# S32K142W_M4 register map
Vendor: NXP Semiconductors; File version: 1.0
CPU: CM4 r0p1, little endian, MPU, FPU, VTOR, 4 interrupt priority bits
Registers are 32-bit, read-write, reset 0x0 unless marked. A register's access mark holds for its fields unless they carry their own. Offsets are from the block's base; [hi:lo] are bit positions; lines under a group give offsets from that group; {n}, {i} and the like mark numbered series; 'fields as' and 'values as' point back to an identical list.

## FLEXCAN0 — CAN
Base 0x40024000
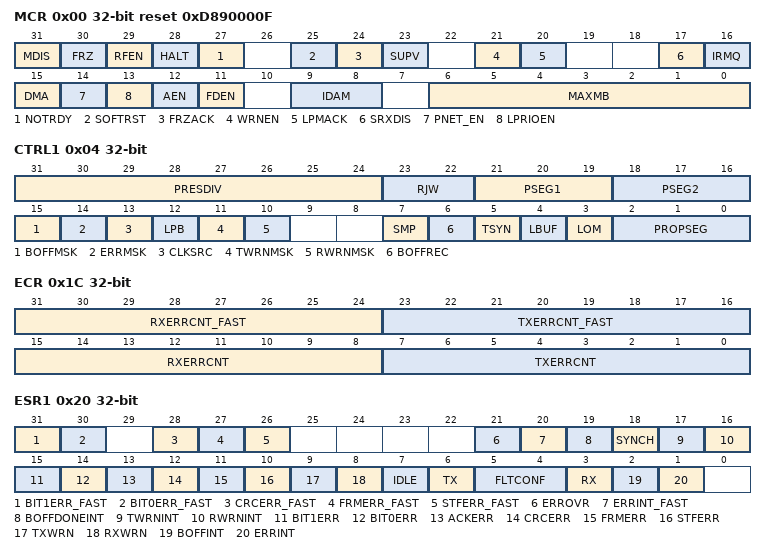
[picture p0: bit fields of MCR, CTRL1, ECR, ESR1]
0x00 MCR reset 0xD890000F — Module Configuration register
  [31] MDIS — Module Disable
    0=flexcan_enabled (Enable the FlexCAN module.); 1=flexcan_disabled (Disable the FlexCAN module.)
  [30] FRZ — Freeze Enable
    0=freeze_mode_disabled (Not enabled to enter Freeze mode.); 1=freeze_mode_enabled (Enabled to enter Freeze mode.)
  [29] RFEN — Rx FIFO Enable
    0=id2 (Rx FIFO not enabled.); 1=id4 (Rx FIFO enabled.)
  [28] HALT — Halt FlexCAN
    0=HALT_disable (No Freeze mode request.); 1=HALT_enable (Enters Freeze mode if the FRZ bit is asserted.)
  [27] NOTRDY ro — FlexCAN Not Ready
    0=id1 (FlexCAN module is either in Normal mode, Listen-Only mode, or Loop-Back mode.); 1=id4 (FlexCAN module is either in Disable mode, Stop mode, or Freeze mode.)
  [25] SOFTRST — Soft Reset
    0=SOFTRST_no_reset_request (No reset request.); 1=SOFTRST_reset_registers (Resets the registers affected by soft reset.)
  [24] FRZACK ro — Freeze Mode Acknowledge
    0=freeze_mode_no (FlexCAN not in Freeze mode, prescaler running.); 1=freeze_mode_yes (FlexCAN in Freeze mode, prescaler stopped.)
  [23] SUPV — Supervisor Mode
    0=id2 (FlexCAN is in User mode. Affected registers allow both Supervisor and Unrestricted accesses.); 1=id4 (FlexCAN is in Supervisor mode. Affected registers allow only Supervisor access. Unrestricted access behaves as though the access was done to an unimplemented register location.)
  [21] WRNEN — Warning Interrupt Enable
    0=TWRNINT_RWRNINT_inactive (TWRNINT and RWRNINT bits are zero, independent of the values in the error counters.); 1=TWRNINT_RWRNINT_active (TWRNINT and RWRNINT bits are set when the respective error counter transitions from less than 96 to greater than or equal to 96.)
  [20] LPMACK ro — Low-Power Mode Acknowledge
    0=low_power_no (FlexCAN is not in a low-power mode.); 1=low_power_yes (FlexCAN is in a low-power mode.)
  [17] SRXDIS — Self Reception Disable
    0=self_reception_enabled; 1=self_reception_disabled
  [16] IRMQ — Individual Rx Masking And Queue Enable
    0=individual_rx_masking_disabled (Individual Rx masking and queue feature are disabled. For backward compatibility with legacy applications, the reading of C/S word locks the MB even if it is EMPTY.); 1=individual_rx_masking_enabled (Individual Rx masking and queue feature are enabled.)
  [15] DMA — DMA Enable
    0=id2 (DMA feature for RX FIFO disabled.); 1=id4 (DMA feature for RX FIFO enabled.)
  [14] PNET_EN — Pretended Networking Enable
    0=PN_disabled (Pretended Networking mode is disabled.); 1=PN_enabled (Pretended Networking mode is enabled.)
  [13] LPRIOEN — Local Priority Enable
    0=local_priority_disabled; 1=local_priority_enabled
  [12] AEN — Abort Enable
    0=abort_disabled; 1=abort_enabled
  [11] FDEN — CAN FD operation enable
    0=CAN_FD_disabled (CAN FD is disabled. FlexCAN is able to receive and transmit messages in CAN 2.0 format.); 1=CAN_FD_enabled (CAN FD is enabled. FlexCAN is able to receive and transmit messages in both CAN FD and CAN 2.0 formats.)
  [9:8] IDAM — ID Acceptance Mode
    0=one_full_ID (Format A: One full ID (standard and extended) per ID filter table element.); 1=two_full_ID (Format B: Two full standard IDs or two partial 14-bit (standard and extended) IDs per ID filter table element.); 2=four_partial_ID (Format C: Four partial 8-bit standard IDs per ID filter table element.); 3=all_frames_rejected (Format D: All frames rejected.)
  [6:0] MAXMB — Number Of The Last Message Buffer
0x04 CTRL1 — Control 1 register
  [31:24] PRESDIV — Prescaler Division Factor
  [23:22] RJW — Resync Jump Width
  [21:19] PSEG1 — Phase Segment 1
  [18:16] PSEG2 — Phase Segment 2
  [15] BOFFMSK — Bus Off Interrupt Mask
    0=bus_off_int_disabled (Bus Off interrupt disabled.); 1=bus_off_int_enabled (Bus Off interrupt enabled.)
  [14] ERRMSK — Error Interrupt Mask
    0=error_int_disabled (Error interrupt disabled.); 1=error_int_enabled (Error interrupt enabled.)
  [13] CLKSRC — CAN Engine Clock Source
    0=oscillator_clock (The CAN engine clock source is the oscillator clock. Under this condition, the oscillator clock frequency must be lower than the bus clock.); 1=peripheral_clock (The CAN engine clock source is the peripheral clock.)
  [12] LPB — Loop Back Mode
    0=loopback_disabled; 1=loopback_enabled
  [11] TWRNMSK — Tx Warning Interrupt Mask
    0=tx_warning_int_disabled (Tx Warning interrupt disabled.); 1=tx_warning_int_enabled (Tx Warning interrupt enabled.)
  [10] RWRNMSK — Rx Warning Interrupt Mask
    0=rx_warning_int_disabled (Rx Warning interrupt disabled.); 1=rx_warning_int_enabled (Rx Warning interrupt enabled.)
  [7] SMP — CAN Bit Sampling
    0=one_sample (Just one sample is used to determine the bit value.); 1=Three samples are used to determine the value of the received bit: the regular one (sample point) and two preceding samples; a majority rule is used
  [6] BOFFREC — Bus Off Recovery
    0=auto_recover_enabled (Automatic recovering from Bus Off state enabled.); 1=auto_recover_disabled (Automatic recovering from Bus Off state disabled.)
  [5] TSYN — Timer Sync
    0=timer_sync_disabled (Timer sync feature disabled); 1=timer_sync_enabled (Timer sync feature enabled)
  [4] LBUF — Lowest Buffer Transmitted First
    0=highest_buffer_first (Buffer with highest priority is transmitted first.); 1=lowest_buffer_first (Lowest number buffer is transmitted first.)
  [3] LOM — Listen-Only Mode
    0=listen_only_mode_disabled (Listen-Only mode is deactivated.); 1=listen_only_mode_enabled (FlexCAN module operates in Listen-Only mode.)
  [2:0] PROPSEG — Propagation Segment
0x08 TIMER — Free Running Timer
  [15:0] TIMER — Timer Value
0x10 RXMGMASK reset not defined — Rx Mailboxes Global Mask register
  [31:0] MG — Rx Mailboxes Global Mask Bits
0x14 RX14MASK reset not defined
  [31:0] RX14M — Rx Buffer 14 Mask Bits
0x18 RX15MASK reset not defined
  [31:0] RX15M — Rx Buffer 15 Mask Bits
0x1C ECR — Error Counter
  [31:24] RXERRCNT_FAST — Receive Error Counter for fast bits
  [23:16] TXERRCNT_FAST — Transmit Error Counter for fast bits
  [15:8] RXERRCNT — Receive Error Counter
  [7:0] TXERRCNT — Transmit Error Counter
0x20 ESR1 — Error and Status 1 register
  [31] BIT1ERR_FAST ro — Bit1 Error in the Data Phase of CAN FD frames with the BRS bit set
    0=bit1_error_no (No such occurrence.); 1=bit1_error_yes (At least one bit sent as recessive is received as dominant.)
  [30] BIT0ERR_FAST ro — Bit0 Error in the Data Phase of CAN FD frames with the BRS bit set
    0=bit0_error_no (No such occurrence.); 1=bit0_error_yes (At least one bit sent as dominant is received as recessive.)
  [28] CRCERR_FAST ro — Cyclic Redundancy Check Error in the CRC field of CAN FD frames with the BRS bit set
    0=CRC_error_no (No such occurrence.); 1=CRC_error_yes (A CRC error occurred since last read of this register.)
  [27] FRMERR_FAST ro — Form Error in the Data Phase of CAN FD frames with the BRS bit set
    0=form_error_no (No such occurrence.); 1=form_error_yes (A form error occurred since last read of this register.)
  [26] STFERR_FAST ro — Stuffing Error in the Data Phase of CAN FD frames with the BRS bit set
    0=stuffing_error_no (No such occurrence.); 1=stuffing_error_yes (A stuffing error occurred since last read of this register.)
  [21] ERROVR write-1-clears — Error Overrun
    0=overrun_not_occurred (Overrun has not occurred.); 1=overrun_occurred (Overrun has occurred.)
  [20] ERRINT_FAST write-1-clears — Error interrupt for errors detected in Data Phase of CAN FD frames with BRS bit set
    0=errors_data_phase_no (No such occurrence.); 1=errors_data_phase_yes (Indicates setting of any error bit detected in the data phase of CAN FD frames with the BRS bit set.)
  [19] BOFFDONEINT write-1-clears — Bus Off Done Interrupt
    0=bus_off_not_done (No such occurrence.); 1=bus_off_done (FlexCAN module has completed Bus Off process.)
  [18] SYNCH ro — CAN Synchronization Status
    0=CAN_bus_sync_no (FlexCAN is not synchronized to the CAN bus.); 1=CAN_bus_sync_yes (FlexCAN is synchronized to the CAN bus.)
  [17] TWRNINT write-1-clears — Tx Warning Interrupt Flag
    0=Tx_warning_int_no (No such occurrence.); 1=Tx_warning_int_yes (The Tx error counter transitioned from less than 96 to greater than or equal to 96.)
  [16] RWRNINT write-1-clears — Rx Warning Interrupt Flag
    0=Rx_warning_int_no (No such occurrence.); 1=Rx_warning_int_yes (The Rx error counter transitioned from less than 96 to greater than or equal to 96.)
  [15] BIT1ERR ro — Bit1 Error
    values as BIT1ERR_FAST
  [14] BIT0ERR ro — Bit0 Error
    values as BIT0ERR_FAST
  [13] ACKERR ro — Acknowledge Error
    0=ACK_error_no (No such occurrence.); 1=ACK_error_yes (An ACK error occurred since last read of this register.)
  [12] CRCERR ro — Cyclic Redundancy Check Error
    values as CRCERR_FAST
  [11] FRMERR ro — Form Error
    0=form_error_no (No such occurrence.); 1=form_error_yes (A Form Error occurred since last read of this register.)
  [10] STFERR ro — Stuffing Error
    values as STFERR_FAST
  [9] TXWRN ro — TX Error Warning
    0=TXERRCNT_LT_96 (No such occurrence.); 1=TXERRCNT_GTE_96 (TXERRCNT is greater than or equal to 96.)
  [8] RXWRN ro — Rx Error Warning
    0=RXERRCNT_LT_96 (No such occurrence.); 1=RXERRCNT_GTE_96 (RXERRCNT is greater than or equal to 96.)
  [7] IDLE ro
    0=can_bus_not_idle (No such occurrence.); 1=can_bus_idle (CAN bus is now IDLE.)
  [6] TX ro — FlexCAN In Transmission
    0=transmit_message_no (FlexCAN is not transmitting a message.); 1=transmit_message_yes (FlexCAN is transmitting a message.)
  [5:4] FLTCONF ro — Fault Confinement State
    0=error_active; 1=error_passive; 0b1x=bus_off
  [3] RX ro — FlexCAN In Reception
    0=DISABLE (FlexCAN is not receiving a message.); 1=ENABLE (FlexCAN is receiving a message.)
  [2] BOFFINT write-1-clears — Bus Off Interrupt
    0=DISABLE (No such occurrence.); 1=ENABLE (FlexCAN module entered Bus Off state.)
  [1] ERRINT write-1-clears — Error Interrupt
    0=DISABLE (No such occurrence.); 1=ENABLE (Indicates setting of any error bit in the Error and Status register.)
0x24 IMASK2 — Interrupt Masks 2 register
  [31:0] BUF63TO32M — Buffer MB i Mask
0x28 IMASK1 — Interrupt Masks 1 register
  [31:0] BUF31TO0M — Buffer MB i Mask
0x2C IFLAG2 — Interrupt Flags 2 register
  [31:0] BUF63TO32I write-1-clears — Buffer MB i Interrupt
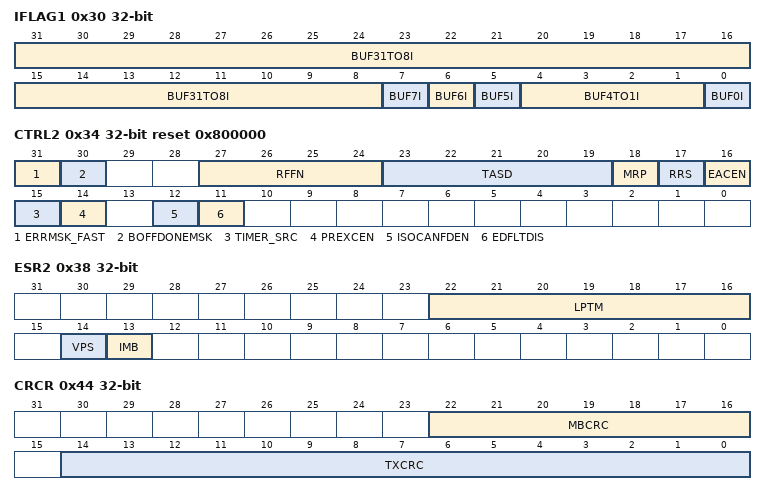
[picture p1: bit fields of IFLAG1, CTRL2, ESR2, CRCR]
0x30 IFLAG1 — Interrupt Flags 1 register
  [31:8] BUF31TO8I write-1-clears — Buffer MBi Interrupt
  [7] BUF7I write-1-clears — Buffer MB7 Interrupt Or Rx FIFO Overflow
    0=id2 (No occurrence of MB7 completing transmission/reception when MCR[RFEN]=0, or of Rx FIFO overflow when MCR[RFEN]=1); 1=id4 (MB7 completed transmission/reception when MCR[RFEN]=0, or Rx FIFO overflow when MCR[RFEN]=1)
  [6] BUF6I write-1-clears — Buffer MB6 Interrupt Or Rx FIFO Warning
    0=id2 (No occurrence of MB6 completing transmission/reception when MCR[RFEN]=0, or of Rx FIFO almost full when MCR[RFEN]=1); 1=id4 (MB6 completed transmission/reception when MCR[RFEN]=0, or Rx FIFO almost full when MCR[RFEN]=1)
  [5] BUF5I write-1-clears — Buffer MB5 Interrupt Or Frames available in Rx FIFO
    0=id2 (No occurrence of MB5 completing transmission/reception when MCR[RFEN]=0, or of frame(s) available in the FIFO, when MCR[RFEN]=1); 1=id4 (MB5 completed transmission/reception when MCR[RFEN]=0, or frame(s) available in the Rx FIFO when MCR[RFEN]=1. It generates a DMA request in case of MCR[RFEN] and MCR[DMA] are enabled.)
  [4:1] BUF4TO1I write-1-clears — Buffer MB i Interrupt Or Reserved
  [0] BUF0I write-1-clears — Buffer MB0 Interrupt Or Clear FIFO bit
    0=buffer_Tx_Rx_not_complete (The corresponding buffer has no occurrence of successfully completed transmission or reception when MCR[RFEN]=0.); 1=buffer_Tx_Rx_complete (The corresponding buffer has successfully completed transmission or reception when MCR[RFEN]=0.)
0x34 CTRL2 reset 0x800000 — Control 2 register
  [31] ERRMSK_FAST — Error Interrupt Mask for errors detected in the data phase of fast CAN FD frames
    0=DISABLE (ERRINT_FAST error interrupt disabled.); 1=ENABLE (ERRINT_FAST error interrupt enabled.)
  [30] BOFFDONEMSK — Bus Off Done Interrupt Mask
    0=DISABLE (Bus off done interrupt disabled.); 1=ENABLE (Bus off done interrupt enabled.)
  [27:24] RFFN — Number Of Rx FIFO Filters
  [23:19] TASD — Tx Arbitration Start Delay
  [18] MRP — Mailboxes Reception Priority
    0=id2 (Matching starts from Rx FIFO or Enhanced Rx FIFO and continues on mailboxes.); 1=id4 (Matching starts from mailboxes and continues on Rx FIFO.)
  [17] RRS — Remote Request Storing
    0=remote_response_frame_not_generated (Remote response frame is generated.); 1=remote_response_frame_generated (Remote request frame is stored.)
  [16] EACEN — Entire Frame Arbitration Field Comparison Enable For Rx Mailboxes
    0=RTR_compare_no (Rx mailbox filter's IDE bit is always compared and RTR is never compared despite mask bits.); 1=RTR_compare_yes (Enables the comparison of both Rx mailbox filter's IDE and RTR bit with their corresponding bits within the incoming frame. Mask bits do apply.)
  [15] TIMER_SRC — Timer Source
    0=CAN_bit_clock (The free running timer is clocked by the CAN bit clock, which defines the baud rate on the CAN bus.); 1=external_clock (The free running timer is clocked by an external time tick. The period can be either adjusted to be equal to the baud rate on the CAN bus, or a different value as required. See the device-specific section for details about the external time tick.)
  [14] PREXCEN — Protocol Exception Enable
    0=DISABLE (Protocol exception is disabled.); 1=ENABLE (Protocol exception is enabled.)
  [12] ISOCANFDEN — ISO CAN FD Enable
    0=non_ISO (FlexCAN operates using the non-ISO CAN FD protocol.); 1=ISO (FlexCAN operates using the ISO CAN FD protocol (ISO 11898-1).)
  [11] EDFLTDIS — Edge Filter Disable
    0=ENABLE (Edge filter is enabled); 1=DISABLE (Edge filter is disabled)
0x38 ESR2 ro — Error and Status 2 register
  [22:16] LPTM — Lowest Priority Tx Mailbox
  [14] VPS — Valid Priority Status
    0=invalid (Contents of IMB and LPTM are invalid.); 1=valid (Contents of IMB and LPTM are valid.)
  [13] IMB — Inactive Mailbox
    0=inactive_mailbox_no (If ESR2[VPS] is asserted, the ESR2[LPTM] is not an inactive mailbox.); 1=inactive_mailbox_yes (If ESR2[VPS] is asserted, there is at least one inactive mailbox. LPTM content is the number of the first one.)
0x44 CRCR ro — CRC register
  [22:16] MBCRC — CRC Mailbox
  [14:0] TXCRC — Transmitted CRC value
0x48 RXFGMASK reset not defined — Rx FIFO Global Mask register
  [31:0] FGM — Rx FIFO Global Mask Bits
0x4C RXFIR ro reset not defined — Rx FIFO Information register
  [8:0] IDHIT — Identifier Acceptance Filter Hit Indicator
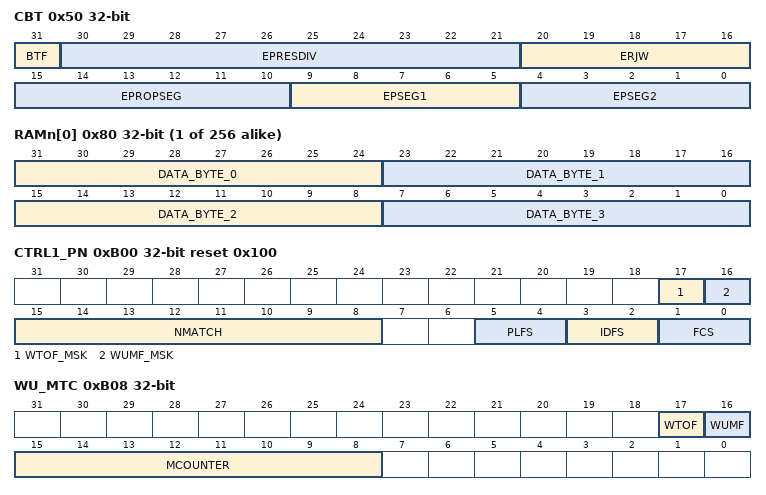
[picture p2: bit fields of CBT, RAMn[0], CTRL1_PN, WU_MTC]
0x50 CBT — CAN Bit Timing register
  [31] BTF — Bit Timing Format Enable
    0=DISABLE (Extended bit time definitions disabled.); 1=ENABLE (Extended bit time definitions enabled.)
  [30:21] EPRESDIV — Extended Prescaler Division Factor
  [20:16] ERJW — Extended Resync Jump Width
  [15:10] EPROPSEG — Extended Propagation Segment
  [9:5] EPSEG1 — Extended Phase Segment 1
  [4:0] EPSEG2 — Extended Phase Segment 2
{0x80+4i} RAMn[{i}] (i=0..255) — Embedded RAM
  [31-8n:24-8n] DATA_BYTE_{n} (n=0..3) — Data byte {n} of Rx/Tx frame.
{0x880+4i} RXIMR[{i}] (i=0..63) reset not defined — Rx Individual Mask registers
  [31:0] MI — Individual Mask Bits
0xB00 CTRL1_PN reset 0x100 — Pretended Networking Control 1 register
  [17] WTOF_MSK — Wake Up by Timeout Flag Mask Bit
    0=DISABLE (Timeout wakeup event is disabled); 1=ENABLE (Timeout wakeup event is enabled)
  [16] WUMF_MSK — Wake Up by Match Flag Mask Bit
    0=DISABLE (Wakeup match event is disabled); 1=ENABLE (Wakeup match event is enabled)
  [15:8] NMATCH — Number of Messages Matching the Same Filtering Criteria
    1=match_1 (Received message must match the predefined filtering criteria for ID and/or PL once before generating a wakeup event.); 2=match_2 (Received message must match the predefined filtering criteria for ID and/or PL twice before generating a wakeup event.); 255=match_255 (Received message must match the predefined filtering criteria for ID and/or PL 255 times before generating a wakeup event.)
  [5:4] PLFS — Payload Filtering Selection
    0=match_exact (Match upon a payload contents against an exact target value); 1=match_GTE (Match upon a payload value greater than or equal to a specified target value); 2=match_LTE (Match upon a payload value smaller than or equal to a specified target value); 3=match_range (Match upon a payload value inside a range, greater than or equal to a specified lower limit, and smaller than or equal to a specified upper limit)
  [3:2] IDFS — ID Filtering Selection
    0=match_exact (Match upon ID contents against an exact target value); 1=match_GTE (Match upon an ID value greater than or equal to a specified target value); 2=match_LTE (Match upon an ID value smaller than or equal to a specified target value); 3=match_range (Match upon an ID value inside a range, greater than or equal to a specified lower limit, and smaller than or equal to a specified upper limit)
  [1:0] FCS — Filtering Combination Selection
    0=ID_filtering (Message ID filtering only); 1=ID_payload_filtering (Message ID filtering and payload filtering); 2=ID_filtering_number (Message ID filtering occurring a specified number of times); 3=ID_payload_filtering_number (Message ID filtering and payload filtering a specified number of times)
0xB04 CTRL2_PN — Pretended Networking Control 2 register
  [15:0] MATCHTO — Timeout for No Message Matching the Filtering Criteria
0xB08 WU_MTC — Pretended Networking Wake Up Match register
  [17] WTOF write-1-clears — Wake Up by Timeout Flag Bit
    0=No wakeup by timeout event detected; 1=Wakeup by timeout event detected
  [16] WUMF write-1-clears — Wake Up by Match Flag Bit
    0=no_match (No wakeup by match event detected); 1=match (Wakeup by match event detected)
  [15:8] MCOUNTER ro — Number of Matches when in Pretended Networking
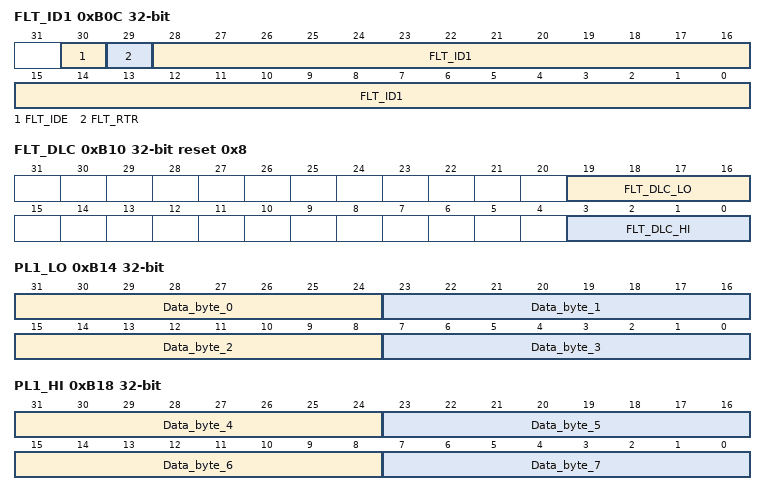
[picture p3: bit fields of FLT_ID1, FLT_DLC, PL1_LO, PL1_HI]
0xB0C FLT_ID1 — Pretended Networking ID Filter 1 register
  [30] FLT_IDE — ID Extended Filter
    0=standard (Accept standard frame format); 1=extended (Accept extended frame format)
  [29] FLT_RTR — Remote Transmission Request Filter
    0=Reject remote frame (accept data frame); 1=Accept remote frame
  [28:0] FLT_ID1 — ID Filter 1 for Pretended Networking filtering
0xB10 FLT_DLC reset 0x8 — Pretended Networking DLC Filter register
  [19:16] FLT_DLC_LO — Lower Limit for Length of Data Bytes Filter
  [3:0] FLT_DLC_HI — Upper Limit for Length of Data Bytes Filter
0xB14 PL1_LO — Pretended Networking Payload Low Filter 1 register
  [31-8n:24-8n] Data_byte_{n} (n=0..3) — Payload Filter 1 low order bits for Pretended Networking payload filtering corresponding to data byte {n}.
0xB18 PL1_HI — Pretended Networking Payload High Filter 1 register
  [63-8n:56-8n] Data_byte_{n} (n=4..7) — Payload Filter 1 high order bits for Pretended Networking payload filtering corresponding to data byte {n}.
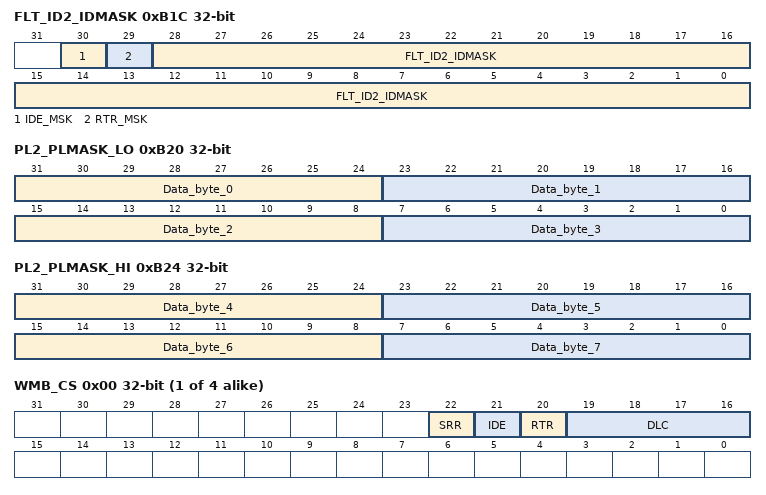
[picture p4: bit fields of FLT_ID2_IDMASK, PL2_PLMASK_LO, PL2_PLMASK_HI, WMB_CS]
0xB1C FLT_ID2_IDMASK — Pretended Networking ID Filter 2 Register / ID Mask register
  [30] IDE_MSK — ID Extended Mask Bit
    0=frame_format_no (The corresponding bit in the filter is "don't care"); 1=frame_format_yes (The corresponding bit in the filter is checked)
  [29] RTR_MSK — Remote Transmission Request Mask Bit
    0=frame_type_no (The corresponding bit in the filter is "don't care"); 1=frame_type_yes (The corresponding bit in the filter is checked)
  [28:0] FLT_ID2_IDMASK — ID Filter 2 for Pretended Networking Filtering / ID Mask Bits for Pretended Networking ID Filtering
0xB20 PL2_PLMASK_LO — Pretended Networking Payload Low Filter 2 Register / Payload Low Mask register
  [31-8n:24-8n] Data_byte_{n} (n=0..3) — Payload Filter 2 low order bits / Payload Mask low order bits for Pretended Networking payload filtering corresponding to the data byte {n}.
0xB24 PL2_PLMASK_HI — Pretended Networking Payload High Filter 2 low order bits / Payload High Mask register
  [63-8n:56-8n] Data_byte_{n} (n=4..7) — Payload Filter 2 high order bits / Payload Mask high order bits for Pretended Networking payload filtering corresponding to the data byte {n}.
{0xB40+0x10*i} WMB[{i}] (i=0..3) group
  0x00 WMB_CS ro — Wake Up Message Buffer register for C/S
    [22] SRR — Substitute Remote Request
    [21] IDE — ID Extended Bit
      0=standard (Frame format is standard); 1=extended (Frame format is extended)
    [20] RTR — Remote Transmission Request Bit
      0=not_remote (Frame is data one (not remote)); 1=remote (Frame is a remote one)
    [19:16] DLC — Length of Data in Bytes
  0x04 WMB_ID ro — Wake Up Message Buffer Register for ID
    [28:0] ID — Received ID under Pretended Networking mode
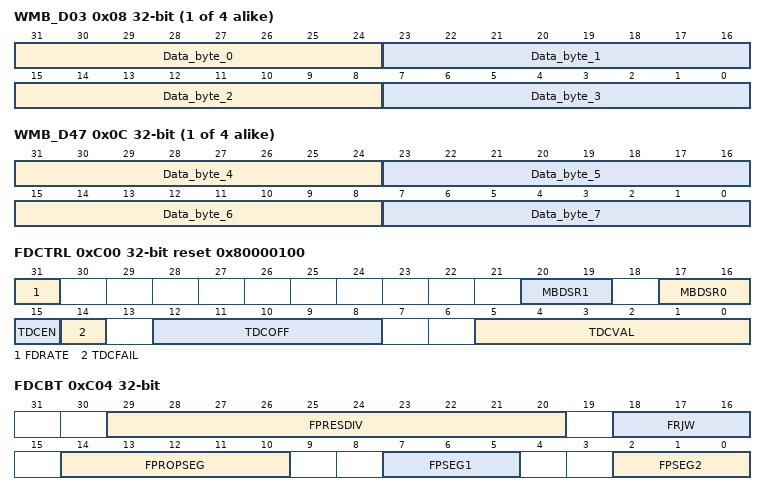
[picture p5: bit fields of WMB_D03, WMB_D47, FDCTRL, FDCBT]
  0x08 WMB_D03 ro — Wake Up Message Buffer Register for Data 0-3
    [31-8n:24-8n] Data_byte_{n} (n=0..3) — Received payload corresponding to the data byte {n} under Pretended Networking mode
  0x0C WMB_D47 ro — Wake Up Message Buffer Register Data 4-7
    [63-8n:56-8n] Data_byte_{n} (n=4..7) — Received payload corresponding to the data byte {n} under Pretended Networking mode
0xC00 FDCTRL reset 0x80000100 — CAN FD Control register
  [31] FDRATE — Bit Rate Switch Enable
    0=nominal (Transmit a frame in nominal rate. The BRS bit in the Tx MB has no effect.); 1=bit_rate_switching (Transmit a frame with bit rate switching if the BRS bit in the Tx MB is recessive.)
  [20:19] MBDSR1 — Message Buffer Data Size for Region 1
    0=R1_8_bytes (Selects 8 bytes per message buffer.); 1=R1_16_bytes (Selects 16 bytes per message buffer.); 2=R1_32_bytes (Selects 32 bytes per message buffer.); 3=R1_64_bytes (Selects 64 bytes per message buffer.)
  [17:16] MBDSR0 — Message Buffer Data Size for Region 0
    0=R0_8_bytes (Selects 8 bytes per message buffer.); 1=R0_16_bytes (Selects 16 bytes per message buffer.); 2=R0_32_bytes (Selects 32 bytes per message buffer.); 3=R0_64_bytes (Selects 64 bytes per message buffer.)
  [15] TDCEN — Transceiver Delay Compensation Enable
    0=DISABLE (TDC is disabled); 1=ENABLE (TDC is enabled)
  [14] TDCFAIL write-1-clears — Transceiver Delay Compensation Fail
    0=in_range (Measured loop delay is in range.); 1=out_of_range (Measured loop delay is out of range.)
  [12:8] TDCOFF — Transceiver Delay Compensation Offset
  [5:0] TDCVAL ro — Transceiver Delay Compensation Value
0xC04 FDCBT — CAN FD Bit Timing register
  [29:20] FPRESDIV — Fast Prescaler Division Factor
  [18:16] FRJW — Fast Resync Jump Width
  [14:10] FPROPSEG — Fast Propagation Segment
  [7:5] FPSEG1 — Fast Phase Segment 1
  [2:0] FPSEG2 — Fast Phase Segment 2
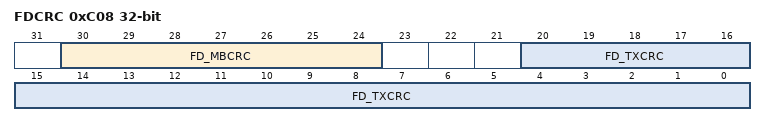
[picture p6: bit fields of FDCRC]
0xC08 FDCRC ro — CAN FD CRC register
  [30:24] FD_MBCRC — CRC Mailbox Number for FD_TXCRC
  [20:0] FD_TXCRC — Extended Transmitted CRC value

## FLEXCAN1 — CAN
Base 0x40025000
Registers as FLEXCAN0, without CTRL1_PN, CTRL2_PN, WU_MTC, FLT_ID1, FLT_DLC, PL1_LO, PL1_HI, FLT_ID2_IDMASK, PL2_PLMASK_LO, PL2_PLMASK_HI, WMB[*]; these are added or differ:
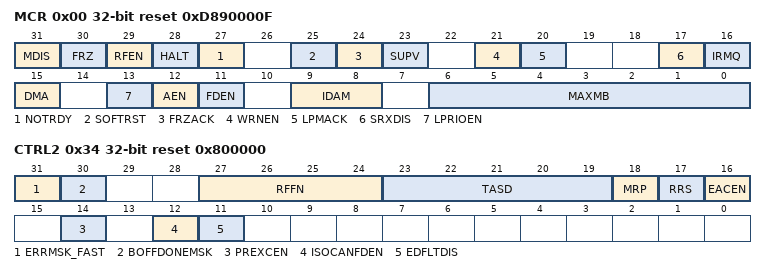
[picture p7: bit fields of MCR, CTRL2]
0x00 MCR reset 0xD890000F — Module Configuration register
  [31] MDIS — Module Disable
    0=flexcan_enabled (Enable the FlexCAN module.); 1=flexcan_disabled (Disable the FlexCAN module.)
  [30] FRZ — Freeze Enable
    0=freeze_mode_disabled (Not enabled to enter Freeze mode.); 1=freeze_mode_enabled (Enabled to enter Freeze mode.)
  [29] RFEN — Rx FIFO Enable
    0=id2 (Rx FIFO not enabled.); 1=id4 (Rx FIFO enabled.)
  [28] HALT — Halt FlexCAN
    0=HALT_disable (No Freeze mode request.); 1=HALT_enable (Enters Freeze mode if the FRZ bit is asserted.)
  [27] NOTRDY ro — FlexCAN Not Ready
    0=id1 (FlexCAN module is either in Normal mode, Listen-Only mode, or Loop-Back mode.); 1=id4 (FlexCAN module is either in Disable mode, Stop mode, or Freeze mode.)
  [25] SOFTRST — Soft Reset
    0=SOFTRST_no_reset_request (No reset request.); 1=SOFTRST_reset_registers (Resets the registers affected by soft reset.)
  [24] FRZACK ro — Freeze Mode Acknowledge
    0=freeze_mode_no (FlexCAN not in Freeze mode, prescaler running.); 1=freeze_mode_yes (FlexCAN in Freeze mode, prescaler stopped.)
  [23] SUPV — Supervisor Mode
    values as FLEXCAN0.MCR.SUPV
  [21] WRNEN — Warning Interrupt Enable
    values as FLEXCAN0.MCR.WRNEN
  [20] LPMACK ro — Low-Power Mode Acknowledge
    0=low_power_no (FlexCAN is not in a low-power mode.); 1=low_power_yes (FlexCAN is in a low-power mode.)
  [17] SRXDIS — Self Reception Disable
    0=self_reception_enabled; 1=self_reception_disabled
  [16] IRMQ — Individual Rx Masking And Queue Enable
    values as FLEXCAN0.MCR.IRMQ
  [15] DMA — DMA Enable
    0=id2 (DMA feature for RX FIFO disabled.); 1=id4 (DMA feature for RX FIFO enabled.)
  [13] LPRIOEN — Local Priority Enable
    0=local_priority_disabled; 1=local_priority_enabled
  [12] AEN — Abort Enable
    0=abort_disabled; 1=abort_enabled
  [11] FDEN — CAN FD operation enable
    values as FLEXCAN0.MCR.FDEN
  [9:8] IDAM — ID Acceptance Mode
    values as FLEXCAN0.MCR.IDAM
  [6:0] MAXMB — Number Of The Last Message Buffer
0x34 CTRL2 reset 0x800000 — Control 2 register
  [31] ERRMSK_FAST — Error Interrupt Mask for errors detected in the data phase of fast CAN FD frames
    0=DISABLE (ERRINT_FAST error interrupt disabled.); 1=ENABLE (ERRINT_FAST error interrupt enabled.)
  [30] BOFFDONEMSK — Bus Off Done Interrupt Mask
    0=DISABLE (Bus off done interrupt disabled.); 1=ENABLE (Bus off done interrupt enabled.)
  [27:24] RFFN — Number Of Rx FIFO Filters
  [23:19] TASD — Tx Arbitration Start Delay
  [18] MRP — Mailboxes Reception Priority
    0=id2 (Matching starts from Rx FIFO or Enhanced Rx FIFO and continues on mailboxes.); 1=id4 (Matching starts from mailboxes and continues on Rx FIFO.)
  [17] RRS — Remote Request Storing
    0=remote_response_frame_not_generated (Remote response frame is generated.); 1=remote_response_frame_generated (Remote request frame is stored.)
  [16] EACEN — Entire Frame Arbitration Field Comparison Enable For Rx Mailboxes
    values as FLEXCAN0.CTRL2.EACEN
  [14] PREXCEN — Protocol Exception Enable
    0=DISABLE (Protocol exception is disabled.); 1=ENABLE (Protocol exception is enabled.)
  [12] ISOCANFDEN — ISO CAN FD Enable
    0=non_ISO (FlexCAN operates using the non-ISO CAN FD protocol.); 1=ISO (FlexCAN operates using the ISO CAN FD protocol (ISO 11898-1).)
  [11] EDFLTDIS — Edge Filter Disable
    0=ENABLE (Edge filter is enabled); 1=DISABLE (Edge filter is disabled)

## Notices in the file
Copyright 2016-2021 NXP
NXP Confidential. This software is owned or controlled by NXP and may only be
used strictly in accordance with the applicable license terms. By expressly
accepting such terms or by downloading, installing, activating and/or otherwise
using the software, you are agreeing that you have read, and that you agree to
comply with and are bound by, such license terms. If you do not agree to be
bound by the applicable license terms, then you may not retain, install,
activate or otherwise use the software. The production use license in
Section 2.3 is expressly granted for this software.
